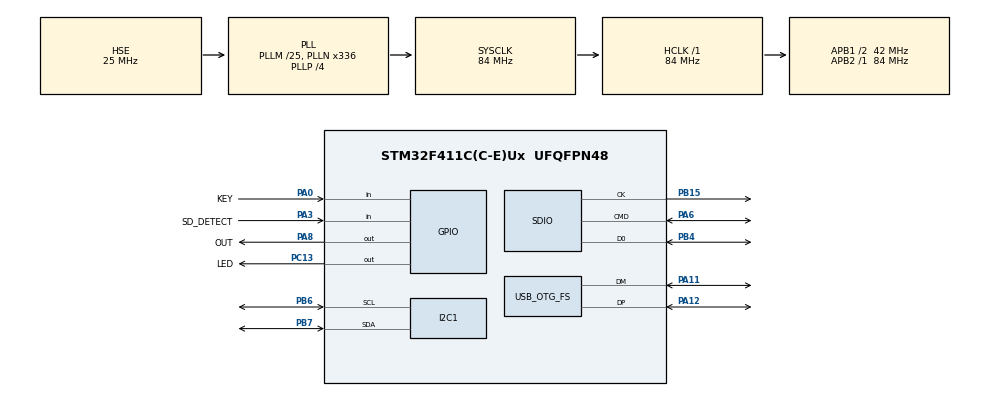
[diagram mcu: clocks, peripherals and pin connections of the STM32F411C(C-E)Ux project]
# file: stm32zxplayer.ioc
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FATFS.BSP.number=1
FATFS._CODE_PAGE=855
FATFS0.BSP.STBoard=false
FATFS0.BSP.api=Unknown
FATFS0.BSP.instance=PA3
FATFS0.BSP.ip=GPIO
FATFS0.BSP.mode=Input
FATFS0.BSP.name=Detect_SDIO
FATFS0.BSP.solution=PA3
I2C1.I2C_Mode=I2C_Fast
Mcu.Family=STM32F4
Mcu.Name=STM32F411C(C-E)Ux
Mcu.Package=UFQFPN48
NVIC.OTG_FS_IRQn=true\:0\:0\:false\:false\:true\:false\:true\:true
NVIC.PriorityGroup=NVIC_PRIORITYGROUP_4
NVIC.TIM1_UP_TIM10_IRQn=true\:0\:0\:false\:false\:true\:true\:true\:true
PA0-WKUP.GPIO_Label=KEY
PA0-WKUP.GPIO_PuPd=GPIO_PULLUP
PA0-WKUP.Signal=GPIO_Input
PA11.Mode=Device_Only
PA11.Signal=USB_OTG_FS_DM
PA12.Mode=Device_Only
PA12.Signal=USB_OTG_FS_DP
PA3.GPIO_Label=SD_DETECT
PA3.Signal=GPIO_Input
PA6.Mode=SD_1_bit
PA6.Signal=SDIO_CMD
PA8.GPIO_Label=OUT
PA8.GPIO_Speed=GPIO_SPEED_FREQ_VERY_HIGH
PA8.Signal=GPIO_Output
PB15.Mode=SD_1_bit
PB15.Signal=SDIO_CK
PB4.Mode=SD_1_bit
PB4.Signal=SDIO_D0
PB6.Mode=I2C
PB6.Signal=I2C1_SCL
PB7.Mode=I2C
PB7.Signal=I2C1_SDA
PC13-ANTI_TAMP.GPIO_Label=LED
PC13-ANTI_TAMP.Signal=GPIO_Output
PH0\ -\ OSC_IN.Mode=HSE-External-Oscillator
PH0\ -\ OSC_IN.Signal=RCC_OSC_IN
PH1\ -\ OSC_OUT.Mode=HSE-External-Oscillator
PH1\ -\ OSC_OUT.Signal=RCC_OSC_OUT
ProjectManager.HeapSize=0x200
ProjectManager.StackSize=0x400
ProjectManager.TargetToolchain=STM32CubeIDE
RCC.48MHZClocksFreq_Value=48000000
RCC.AHBFreq_Value=84000000
RCC.APB1CLKDivider=RCC_HCLK_DIV2
RCC.APB1Freq_Value=42000000
RCC.APB1TimFreq_Value=84000000
RCC.APB2Freq_Value=84000000
RCC.APB2TimFreq_Value=84000000
RCC.CortexFreq_Value=84000000
RCC.HCLKFreq_Value=84000000
RCC.HSE_VALUE=25000000
RCC.HSI_VALUE=16000000
RCC.LSE_VALUE=32768
RCC.PLLM=25
RCC.PLLN=336
RCC.PLLP=RCC_PLLP_DIV4
RCC.PLLQ=7
RCC.SYSCLKFreq_VALUE=84000000
RCC.SYSCLKSource=RCC_SYSCLKSOURCE_PLLCLK
RCC.VCOOutputFreq_Value=336000000
SDIO.ClockDiv=3
TIM1.Period=2167
TIM1.Prescaler=24-1
TIM1.RepetitionCounter=0
USB_DEVICE.CLASS_NAME_FS=MSC
USB_DEVICE.VirtualMode=Msc
USB_DEVICE.VirtualModeFS=Msc_FS
USB_OTG_FS.VirtualMode=Device_Only
VP_FATFS_VS_SDIO.Mode=SDIO
VP_TIM1_VS_ClockSourceINT.Mode=Internal
VP_USB_DEVICE_VS_USB_DEVICE_MSC_FS.Mode=MSC_FS
board=custom

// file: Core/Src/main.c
/* USER CODE BEGIN Header */
/**
  ******************************************************************************
  * @file           : main.c
  * @brief          : Main program body
  ******************************************************************************
  * @attention
  *
  * Copyright (c) 2024 STMicroelectronics.
  * All rights reserved.
  *
  * This software is licensed under terms that can be found in the LICENSE file
  * in the root directory of this software component.
  * If no LICENSE file comes with this software, it is provided AS-IS.
  *
  ******************************************************************************
  */
/* USER CODE END Header */
#include "main.h"
#include "fatfs.h"
#include "usb_device.h"

/* USER CODE BEGIN Includes */

#include "application.h"
/* USER CODE END Includes */

I2C_HandleTypeDef hi2c1;

SD_HandleTypeDef hsd;

TIM_HandleTypeDef htim1;

void SystemClock_Config(void);
static void MX_GPIO_Init(void);
static void MX_I2C1_Init(void);
static void MX_SDIO_SD_Init(void);
static void MX_TIM1_Init(void);

/* USER CODE BEGIN 0 */
void HAL_TIM_PeriodElapsedCallback(TIM_HandleTypeDef *htim)
{
	if(htim->Instance == TIM1) //check if the interrupt comes from TIM1
	{
		app_tim1_update();
		//HAL_GPIO_TogglePin(led13_GPIO_Port, led13_Pin);
	}
}

//void HAL_TIM_OC_DelayElapsedCallback(TIM_HandleTypeDef *htim) {
//	if(htim->Instance == TIM1)
//	{
//		app_tim1_update();
//	}
//}

/* USER CODE END 0 */

int main(void)
{

  /* MCU Configuration--------------------------------------------------------*/

  /* Reset of all peripherals, Initializes the Flash interface and the Systick. */
  HAL_Init();

  /* Configure the system clock */
  SystemClock_Config();

  /* Initialize all configured peripherals */
  MX_GPIO_Init();
  MX_I2C1_Init();
  MX_SDIO_SD_Init();
  MX_FATFS_Init();
  MX_USB_DEVICE_Init();
  MX_TIM1_Init();

  /* Infinite loop */
  /* USER CODE BEGIN WHILE */

  app_init();

  while (1)
  {
	  app_loop();

    /* USER CODE END WHILE */

  }
}

void SystemClock_Config(void)
{
  RCC_OscInitTypeDef RCC_OscInitStruct = {0};
  RCC_ClkInitTypeDef RCC_ClkInitStruct = {0};

  /** Configure the main internal regulator output voltage
  */
  __HAL_RCC_PWR_CLK_ENABLE();
  __HAL_PWR_VOLTAGESCALING_CONFIG(PWR_REGULATOR_VOLTAGE_SCALE1);

  /** Initializes the RCC Oscillators according to the specified parameters
  * in the RCC_OscInitTypeDef structure.
  */
  RCC_OscInitStruct.OscillatorType = RCC_OSCILLATORTYPE_HSE;
  RCC_OscInitStruct.HSEState = RCC_HSE_ON;
  RCC_OscInitStruct.PLL.PLLState = RCC_PLL_ON;
  RCC_OscInitStruct.PLL.PLLSource = RCC_PLLSOURCE_HSE;
  RCC_OscInitStruct.PLL.PLLM = 25;
  RCC_OscInitStruct.PLL.PLLN = 336;
  RCC_OscInitStruct.PLL.PLLP = RCC_PLLP_DIV4;
  RCC_OscInitStruct.PLL.PLLQ = 7;
  if (HAL_RCC_OscConfig(&RCC_OscInitStruct) != HAL_OK)
  {
    Error_Handler();
  }

  /** Initializes the CPU, AHB and APB buses clocks
  */
  RCC_ClkInitStruct.ClockType = RCC_CLOCKTYPE_HCLK|RCC_CLOCKTYPE_SYSCLK
                              |RCC_CLOCKTYPE_PCLK1|RCC_CLOCKTYPE_PCLK2;
  RCC_ClkInitStruct.SYSCLKSource = RCC_SYSCLKSOURCE_PLLCLK;
  RCC_ClkInitStruct.AHBCLKDivider = RCC_SYSCLK_DIV1;
  RCC_ClkInitStruct.APB1CLKDivider = RCC_HCLK_DIV2;
  RCC_ClkInitStruct.APB2CLKDivider = RCC_HCLK_DIV1;

  if (HAL_RCC_ClockConfig(&RCC_ClkInitStruct, FLASH_LATENCY_2) != HAL_OK)
  {
    Error_Handler();
  }
}

static void MX_I2C1_Init(void)
{

  hi2c1.Instance = I2C1;
  hi2c1.Init.ClockSpeed = 400000;
  hi2c1.Init.DutyCycle = I2C_DUTYCYCLE_2;
  hi2c1.Init.OwnAddress1 = 0;
  hi2c1.Init.AddressingMode = I2C_ADDRESSINGMODE_7BIT;
  hi2c1.Init.DualAddressMode = I2C_DUALADDRESS_DISABLE;
  hi2c1.Init.OwnAddress2 = 0;
  hi2c1.Init.GeneralCallMode = I2C_GENERALCALL_DISABLE;
  hi2c1.Init.NoStretchMode = I2C_NOSTRETCH_DISABLE;
  if (HAL_I2C_Init(&hi2c1) != HAL_OK)
  {
    Error_Handler();
  }

}

static void MX_SDIO_SD_Init(void)
{

  hsd.Instance = SDIO;
  hsd.Init.ClockEdge = SDIO_CLOCK_EDGE_RISING;
  hsd.Init.ClockBypass = SDIO_CLOCK_BYPASS_DISABLE;
  hsd.Init.ClockPowerSave = SDIO_CLOCK_POWER_SAVE_DISABLE;
  hsd.Init.BusWide = SDIO_BUS_WIDE_1B;
  hsd.Init.HardwareFlowControl = SDIO_HARDWARE_FLOW_CONTROL_DISABLE;
  hsd.Init.ClockDiv = 3;
  /* USER CODE BEGIN SDIO_Init 2 */

  HAL_SD_Init(&hsd);
  /* USER CODE END SDIO_Init 2 */

}

static void MX_TIM1_Init(void)
{

  TIM_ClockConfigTypeDef sClockSourceConfig = {0};
  TIM_MasterConfigTypeDef sMasterConfig = {0};

  htim1.Instance = TIM1;
  htim1.Init.Prescaler = 24-1;
  htim1.Init.CounterMode = TIM_COUNTERMODE_UP;
  htim1.Init.Period = 2167;
  htim1.Init.ClockDivision = TIM_CLOCKDIVISION_DIV1;
  htim1.Init.RepetitionCounter = 0;
  htim1.Init.AutoReloadPreload = TIM_AUTORELOAD_PRELOAD_DISABLE;
  if (HAL_TIM_Base_Init(&htim1) != HAL_OK)
  {
    Error_Handler();
  }
  sClockSourceConfig.ClockSource = TIM_CLOCKSOURCE_INTERNAL;
  if (HAL_TIM_ConfigClockSource(&htim1, &sClockSourceConfig) != HAL_OK)
  {
    Error_Handler();
  }
  sMasterConfig.MasterOutputTrigger = TIM_TRGO_RESET;
  sMasterConfig.MasterSlaveMode = TIM_MASTERSLAVEMODE_DISABLE;
  if (HAL_TIMEx_MasterConfigSynchronization(&htim1, &sMasterConfig) != HAL_OK)
  {
    Error_Handler();
  }

}

static void MX_GPIO_Init(void)
{
  GPIO_InitTypeDef GPIO_InitStruct = {0};

  /* GPIO Ports Clock Enable */
  __HAL_RCC_GPIOC_CLK_ENABLE();
  __HAL_RCC_GPIOH_CLK_ENABLE();
  __HAL_RCC_GPIOA_CLK_ENABLE();
  __HAL_RCC_GPIOB_CLK_ENABLE();

  /*Configure GPIO pin Output Level */
  HAL_GPIO_WritePin(LED_GPIO_Port, LED_Pin, GPIO_PIN_RESET);

  /*Configure GPIO pin Output Level */
  HAL_GPIO_WritePin(OUT_GPIO_Port, OUT_Pin, GPIO_PIN_RESET);

  /*Configure GPIO pin : LED_Pin */
  GPIO_InitStruct.Pin = LED_Pin;
  GPIO_InitStruct.Mode = GPIO_MODE_OUTPUT_PP;
  GPIO_InitStruct.Pull = GPIO_NOPULL;
  GPIO_InitStruct.Speed = GPIO_SPEED_FREQ_LOW;
  HAL_GPIO_Init(LED_GPIO_Port, &GPIO_InitStruct);

  /*Configure GPIO pin : KEY_Pin */
  GPIO_InitStruct.Pin = KEY_Pin;
  GPIO_InitStruct.Mode = GPIO_MODE_INPUT;
  GPIO_InitStruct.Pull = GPIO_PULLUP;
  HAL_GPIO_Init(KEY_GPIO_Port, &GPIO_InitStruct);

  /*Configure GPIO pin : SD_DETECT_Pin */
  GPIO_InitStruct.Pin = SD_DETECT_Pin;
  GPIO_InitStruct.Mode = GPIO_MODE_INPUT;
  GPIO_InitStruct.Pull = GPIO_NOPULL;
  HAL_GPIO_Init(SD_DETECT_GPIO_Port, &GPIO_InitStruct);

  /*Configure GPIO pin : OUT_Pin */
  GPIO_InitStruct.Pin = OUT_Pin;
  GPIO_InitStruct.Mode = GPIO_MODE_OUTPUT_PP;
  GPIO_InitStruct.Pull = GPIO_NOPULL;
  GPIO_InitStruct.Speed = GPIO_SPEED_FREQ_VERY_HIGH;
  HAL_GPIO_Init(OUT_GPIO_Port, &GPIO_InitStruct);

}

void Error_Handler(void)
{
  __disable_irq();
  while (1)
  {
  }
}
